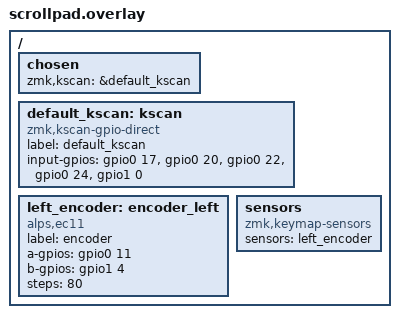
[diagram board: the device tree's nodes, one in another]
/ {
    chosen {
        zmk,kscan = &default_kscan;
    };

    default_kscan: kscan {
        compatible = "zmk,kscan-gpio-direct";
        label = "default_kscan";

        input-gpios =
            <&gpio0 17 (GPIO_ACTIVE_HIGH | GPIO_PULL_UP)>,
            <&gpio0 20 (GPIO_ACTIVE_HIGH | GPIO_PULL_UP)>,
            <&gpio0 22 (GPIO_ACTIVE_HIGH | GPIO_PULL_UP)>,
            <&gpio0 24 (GPIO_ACTIVE_HIGH | GPIO_PULL_UP)>,
            <&gpio1 0 (GPIO_ACTIVE_HIGH | GPIO_PULL_UP)>;
    };

    left_encoder: encoder_left {
        compatible = "alps,ec11";
        label = "encoder";
        a-gpios = <&gpio0 11 (GPIO_ACTIVE_HIGH | GPIO_PULL_UP)>;
        b-gpios = <&gpio1 4 (GPIO_ACTIVE_HIGH | GPIO_PULL_UP)>;
        steps = <80>;
        status = "okay";
    };

    sensors {
        compatible = "zmk,keymap-sensors";
        sensors = <&left_encoder>;
    };
};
